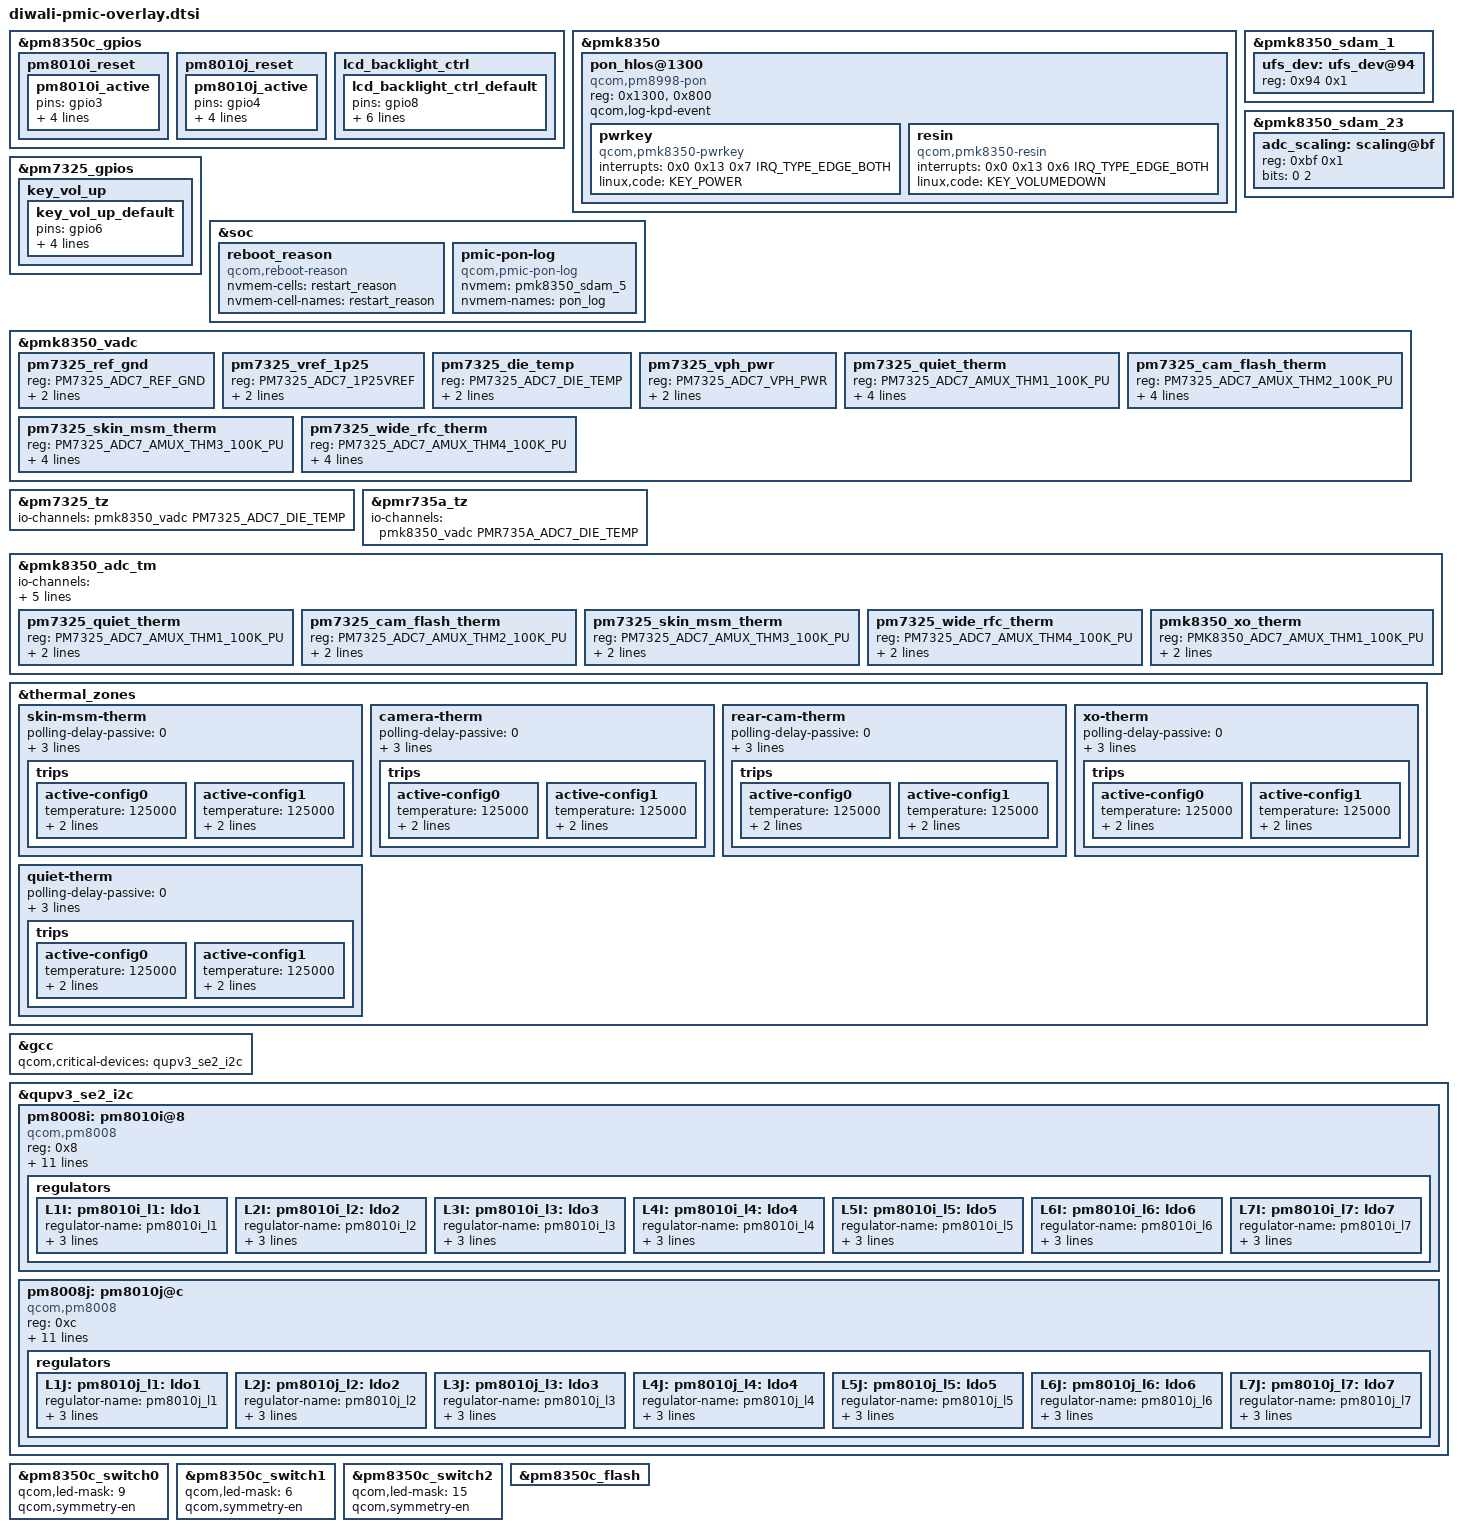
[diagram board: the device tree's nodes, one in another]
// SPDX-License-Identifier: BSD-3-Clause
/*
 * Copyright (c) Qualcomm Technologies, Inc. and/or its subsidiaries.
 */

#include <dt-bindings/pinctrl/qcom,pmic-gpio.h>
#include <dt-bindings/iio/qcom,spmi-adc7-pm7325.h>

#include "pmk8350.dtsi"
#include "pm8350c.dtsi"
#include "pm7325.dtsi"
#include "pmr735a.dtsi"

&pm8350c_gpios {
	pm8010i_reset {
		pm8010i_active: pm8010i_active {
			pins = "gpio3";
			function = "normal";
			bias-disable;
			output-high;
			power-source = <0>;
		};
	};

	pm8010j_reset {
		pm8010j_active: pm8010j_active {
			pins = "gpio4";
			function = "normal";
			bias-disable;
			output-high;
			power-source = <0>;
		};
	};
};

&pmk8350 {
	/delete-node/ pon_pbs@800;
	/delete-node/ pon_hlos@1300;

	pon_hlos@1300 {
		compatible = "qcom,pm8998-pon";
		reg = <0x1300>, <0x800>;
		reg-names = "pon_hlos", "pon_pbs";
		qcom,log-kpd-event;

		pwrkey {
			compatible = "qcom,pmk8350-pwrkey";
			interrupts = <0x0 0x13 0x7 IRQ_TYPE_EDGE_BOTH>;
			linux,code = <KEY_POWER>;
		};

		resin {
			compatible = "qcom,pmk8350-resin";
			interrupts = <0x0 0x13 0x6 IRQ_TYPE_EDGE_BOTH>;
			linux,code = <KEY_VOLUMEDOWN>;
		};
	};
};

&pmk8350_sdam_1 {
	ufs_dev: ufs_dev@94 {
		reg = <0x94 0x1>;
	};
};

&pmk8350_sdam_23 {
	adc_scaling: scaling@bf {
		reg = <0xbf 0x1>;
		bits = <0 2>;
	};
};

&pm7325_gpios {
	key_vol_up {
		key_vol_up_default: key_vol_up_default {
			pins = "gpio6";
			function = "normal";
			input-enable;
			bias-pull-up;
			power-source = <1>;
		};
	};
};

&pm8350c_gpios {
	lcd_backlight_ctrl {
		lcd_backlight_ctrl_default: lcd_backlight_ctrl_default {
			pins = "gpio8";
			function = "func1";
			input-disable;
			output-enable;
			bias-disable;
			power-source = <1>;       /* 1.8V */
			qcom,drive-strength = <2>;
		};
	};
};

&soc {
	reboot_reason {
		compatible = "qcom,reboot-reason";
		nvmem-cells = <&restart_reason>;
		nvmem-cell-names = "restart_reason";
	};

	pmic-pon-log {
		compatible = "qcom,pmic-pon-log";
		nvmem = <&pmk8350_sdam_5>;
		nvmem-names = "pon_log";
	};
};

&pmk8350_vadc {
	/delete-node/ pm8350_ref_gnd;
	/delete-node/ pm8350_vref_1p25;
	/delete-node/ pm8350_die_temp;
	/delete-node/ pm8350_vph_pwr;

	/delete-node/ pm8350b_ref_gnd;
	/delete-node/ pm8350b_vref_1p25;
	/delete-node/ pm8350b_die_temp;
	/delete-node/ pm8350b_vph_pwr;
	/delete-node/ pm8350b_vbat_sns;

	/delete-node/ pmr735b_ref_gnd;
	/delete-node/ pmr735b_vref_1p25;
	/delete-node/ pmr735b_die_temp;

	/* PM7325 Channel nodes */
	pm7325_ref_gnd {
		reg = <PM7325_ADC7_REF_GND>;
		label = "pm7325_ref_gnd";
		qcom,pre-scaling = <1 1>;
	};

	pm7325_vref_1p25 {
		reg = <PM7325_ADC7_1P25VREF>;
		label = "pm7325_vref_1p25";
		qcom,pre-scaling = <1 1>;
	};

	pm7325_die_temp {
		reg = <PM7325_ADC7_DIE_TEMP>;
		label = "pm7325_die_temp";
		qcom,pre-scaling = <1 1>;
	};

	pm7325_vph_pwr {
		reg = <PM7325_ADC7_VPH_PWR>;
		label = "pm7325_vph_pwr";
		qcom,pre-scaling = <1 3>;
	};

	pm7325_quiet_therm {
		reg = <PM7325_ADC7_AMUX_THM1_100K_PU>;
		label = "pm7325_quiet_therm";
		qcom,ratiometric;
		qcom,hw-settle-time = <200>;
		qcom,pre-scaling = <1 1>;
	};

	pm7325_cam_flash_therm {
		reg = <PM7325_ADC7_AMUX_THM2_100K_PU>;
		label = "pm7325_cam_flash_therm";
		qcom,ratiometric;
		qcom,hw-settle-time = <200>;
		qcom,pre-scaling = <1 1>;
	};

	pm7325_skin_msm_therm {
		reg = <PM7325_ADC7_AMUX_THM3_100K_PU>;
		label = "pm7325_skin_msm_therm";
		qcom,ratiometric;
		qcom,hw-settle-time = <200>;
		qcom,pre-scaling = <1 1>;
	};

	pm7325_wide_rfc_therm {
		reg = <PM7325_ADC7_AMUX_THM4_100K_PU>;
		label = "pm7325_wide_rfc_therm";
		qcom,ratiometric;
		qcom,hw-settle-time = <200>;
		qcom,pre-scaling = <1 1>;
	};
};

&pm7325_tz {
	io-channels = <&pmk8350_vadc PM7325_ADC7_DIE_TEMP>;
	io-channel-names = "thermal";
};

&pmr735a_tz {
	io-channels = <&pmk8350_vadc PMR735A_ADC7_DIE_TEMP>;
	io-channel-names = "thermal";
};

&pmk8350_adc_tm {
	io-channels = <&pmk8350_vadc PM7325_ADC7_AMUX_THM1_100K_PU>,
			<&pmk8350_vadc PM7325_ADC7_AMUX_THM2_100K_PU>,
			<&pmk8350_vadc PM7325_ADC7_AMUX_THM3_100K_PU>,
			<&pmk8350_vadc PM7325_ADC7_AMUX_THM4_100K_PU>,
			<&pmk8350_vadc PMK8350_ADC7_AMUX_THM1_100K_PU>;

	pm7325_quiet_therm {
		reg = <PM7325_ADC7_AMUX_THM1_100K_PU>;
		qcom,ratiometric;
		qcom,hw-settle-time = <200>;
	};

	pm7325_cam_flash_therm {
		reg = <PM7325_ADC7_AMUX_THM2_100K_PU>;
		qcom,ratiometric;
		qcom,hw-settle-time = <200>;
	};

	pm7325_skin_msm_therm {
		reg = <PM7325_ADC7_AMUX_THM3_100K_PU>;
		qcom,ratiometric;
		qcom,hw-settle-time = <200>;
	};

	pm7325_wide_rfc_therm {
		reg = <PM7325_ADC7_AMUX_THM4_100K_PU>;
		qcom,ratiometric;
		qcom,hw-settle-time = <200>;
	};

	pmk8350_xo_therm {
		reg = <PMK8350_ADC7_AMUX_THM1_100K_PU>;
		qcom,ratiometric;
		qcom,hw-settle-time = <200>;
	};
};

&thermal_zones {
	skin-msm-therm {
		polling-delay-passive = <0>;
		polling-delay = <0>;
		thermal-sensors = <&pmk8350_adc_tm PM7325_ADC7_AMUX_THM3_100K_PU>;
		trips {
			active-config0 {
				temperature = <125000>;
				hysteresis = <1000>;
				type = "passive";
			};

			active-config1 {
				temperature = <125000>;
				hysteresis = <1000>;
				type = "passive";
			};
		};
	};

	camera-therm {
		polling-delay-passive = <0>;
		polling-delay = <0>;
		thermal-sensors = <&pmk8350_adc_tm PM7325_ADC7_AMUX_THM2_100K_PU>;
		trips {
			active-config0 {
				temperature = <125000>;
				hysteresis = <1000>;
				type = "passive";
			};

			active-config1 {
				temperature = <125000>;
				hysteresis = <1000>;
				type = "passive";
			};
		};
	};

	rear-cam-therm {
		polling-delay-passive = <0>;
		polling-delay = <0>;
		thermal-sensors = <&pmk8350_adc_tm PM7325_ADC7_AMUX_THM4_100K_PU>;
		trips {
			active-config0 {
				temperature = <125000>;
				hysteresis = <1000>;
				type = "passive";
			};

			active-config1 {
				temperature = <125000>;
				hysteresis = <1000>;
				type = "passive";
			};
		};
	};

	xo-therm {
		polling-delay-passive = <0>;
		polling-delay = <0>;
		thermal-sensors = <&pmk8350_adc_tm PMK8350_ADC7_AMUX_THM1_100K_PU>;
		trips {
			active-config0 {
				temperature = <125000>;
				hysteresis = <1000>;
				type = "passive";
			};

			active-config1 {
				temperature = <125000>;
				hysteresis = <1000>;
				type = "passive";
			};
		};
	};

	quiet-therm {
		polling-delay-passive = <0>;
		polling-delay = <0>;
		thermal-sensors = <&pmk8350_adc_tm PM7325_ADC7_AMUX_THM1_100K_PU>;
		trips {
			active-config0 {
				temperature = <125000>;
				hysteresis = <1000>;
				type = "passive";
			};

			active-config1 {
				temperature = <125000>;
				hysteresis = <1000>;
				type = "passive";
			};
		};
	};
};

/*
 * Each QUP device that's a parent to PMIC must be listed as a critical device
 * to GCC
 */
&gcc {
	qcom,critical-devices = <&qupv3_se2_i2c>;
};

&qupv3_se2_i2c {
	#address-cells = <1>;
	#size-cells = <0>;
	status = "ok";

	pm8008i: pm8010i@8 {
		compatible = "qcom,pm8008";
		reg = <0x8>;
		#address-cells = <1>;
		#size-cells = <0>;
		interrupts-extended = <&tlmm 48 IRQ_TYPE_EDGE_RISING>;
		reset-gpios = <&tlmm 3 GPIO_ACTIVE_LOW>;

		vdd-l1-l2-supply = <&S8B>;
		vdd-l3-l4-supply = <&BOB>;
		vdd-l6-supply = <&BOB>;
		vdd-l7-supply = <&BOB>;

		pinctrl-names = "default";
		pinctrl-0 = <&pm8010i_active>;

		gpio-controller;
		#gpio-cells = <2>;
		gpio-ranges = <&pm8008i 0 0 2>;

		interrupt-controller;
		#interrupt-cells = <2>;
		#thermal-sensor-cells = <0>;

		regulators {
			L1I: pm8010i_l1: ldo1 {
				regulator-name = "pm8010i_l1";
				regulator-min-microvolt = <254000>;
				regulator-max-microvolt = <1200000>;
				regulator-allow-set-load;
			};

			L2I: pm8010i_l2: ldo2 {
				regulator-name = "pm8010i_l2";
				regulator-min-microvolt = <278000>;
				regulator-max-microvolt = <1150000>;
				regulator-allow-set-load;
			};

			L3I: pm8010i_l3: ldo3 {
				regulator-name = "pm8010i_l3";
				regulator-min-microvolt = <2700000>;
				regulator-max-microvolt = <3000000>;
				regulator-allow-set-load;
			};

			L4I: pm8010i_l4: ldo4 {
				regulator-name = "pm8010i_l4";
				regulator-min-microvolt = <2700000>;
				regulator-max-microvolt = <2900000>;
				regulator-allow-set-load;
			};

			L5I: pm8010i_l5: ldo5 {
				regulator-name = "pm8010i_l5";
				regulator-min-microvolt = <1504000>;
				regulator-max-microvolt = <3544000>;
				regulator-allow-set-load;
			};

			L6I: pm8010i_l6: ldo6 {
				regulator-name = "pm8010i_l6";
				regulator-min-microvolt = <2700000>;
				regulator-max-microvolt = <2900000>;
				regulator-allow-set-load;
			};

			L7I: pm8010i_l7: ldo7 {
				regulator-name = "pm8010i_l7";
				regulator-min-microvolt = <2700000>;
				regulator-max-microvolt = <3000000>;
				regulator-allow-set-load;
			};
		};
	};

	pm8008j: pm8010j@c {
		compatible = "qcom,pm8008";
		reg = <0xc>;
		interrupts-extended = <&tlmm 63 IRQ_TYPE_EDGE_RISING>;
		reset-gpios = <&tlmm 4 GPIO_ACTIVE_LOW>;

		vdd-l1-l2-supply = <&S8B>;
		vdd-l5-supply = <&BOB>;
		vdd-l6-supply = <&BOB>;
		vdd-l7-supply = <&BOB>;

		pinctrl-names = "default";
		pinctrl-0 = <&pm8010j_active>;

		gpio-controller;
		#gpio-cells = <2>;
		gpio-ranges = <&pm8008j 0 0 2>;

		interrupt-controller;
		#interrupt-cells = <2>;
		#thermal-sensor-cells = <0>;

		regulators {
			L1J: pm8010j_l1: ldo1 {
				regulator-name = "pm8010j_l1";
				regulator-min-microvolt = <310000>;
				regulator-max-microvolt = <1150000>;
				regulator-allow-set-load;
			};

			L2J: pm8010j_l2: ldo2 {
				regulator-name = "pm8010j_l2";
				regulator-min-microvolt = <358000>;
				regulator-max-microvolt = <1486000>;
				regulator-allow-set-load;
			};

			L3J: pm8010j_l3: ldo3 {
				regulator-name = "pm8010j_l3";
				regulator-min-microvolt = <1632000>;
				regulator-max-microvolt = <1944000>;
				regulator-allow-set-load;
			};

			L4J: pm8010j_l4: ldo4 {
				regulator-name = "pm8010j_l4";
				regulator-min-microvolt = <1548000>;
				regulator-max-microvolt = <1888000>;
				regulator-allow-set-load;
			};

			L5J: pm8010j_l5: ldo5 {
				regulator-name = "pm8010j_l5";
				regulator-min-microvolt = <1504000>;
				regulator-max-microvolt = <3544000>;
				regulator-allow-set-load;
			};

			L6J: pm8010j_l6: ldo6 {
				regulator-name = "pm8010j_l6";
				regulator-min-microvolt = <2700000>;
				regulator-max-microvolt = <2900000>;
				regulator-allow-set-load;
			};

			L7J: pm8010j_l7: ldo7 {
				regulator-name = "pm8010j_l7";
				regulator-min-microvolt = <1504000>;
				regulator-max-microvolt = <3544000>;
				regulator-allow-set-load;
			};
		};
	};
};

&pm8350c_switch0 {
	qcom,led-mask = <9>; /* Channels 1 & 4 */
	qcom,symmetry-en;
};

&pm8350c_switch1 {
	qcom,led-mask = <6>; /* Channels 2 & 3 */
	qcom,symmetry-en;
};

&pm8350c_switch2 {
	qcom,led-mask = <15>; /* All Channels */
	qcom,symmetry-en;
};

&pm8350c_flash {
	status = "ok";
};
